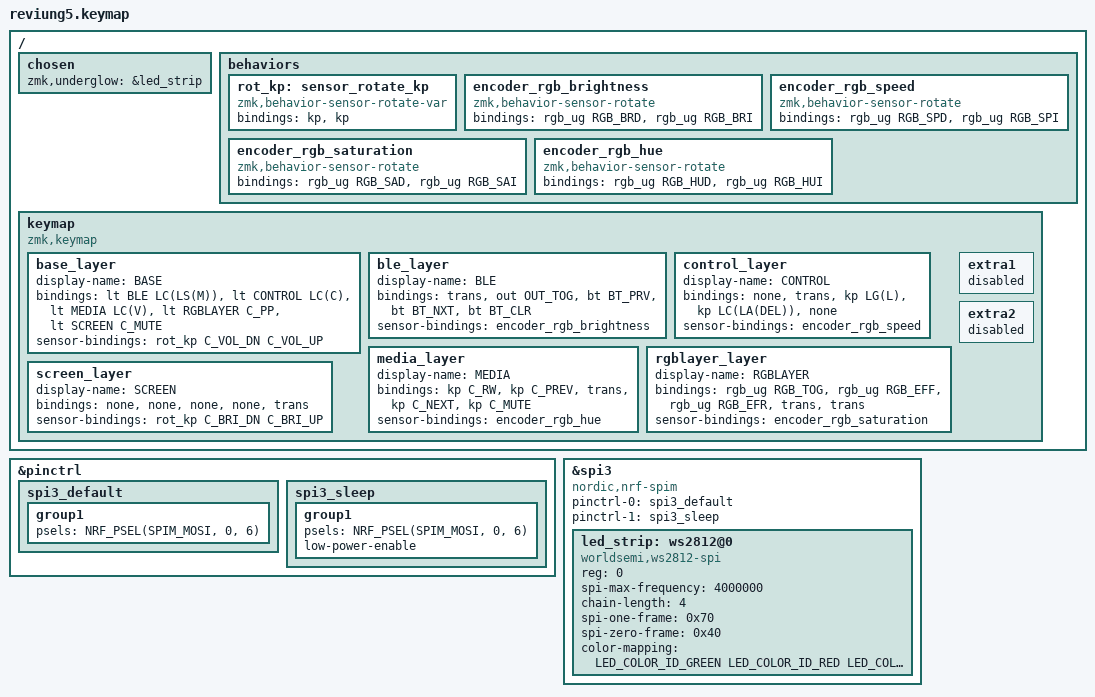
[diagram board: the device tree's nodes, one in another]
/*
 * Copyright (c) 2022 The ZMK Contributors
 *
 * SPDX-License-Identifier: MIT
 */

#include <behaviors.dtsi>
#include <dt-bindings/zmk/keys.h>
#include <dt-bindings/zmk/bt.h>
#include <dt-bindings/zmk/outputs.h>
#include <dt-bindings/led/led.h>
#include <dt-bindings/zmk/rgb.h>

#define BASE 0
#define BLE 1
#define CONTROL 2
#define MEDIA 3
#define RGBLAYER 4
#define SCREEN 5

&pinctrl {
    spi3_default: spi3_default {
        group1 {
            psels = <NRF_PSEL(SPIM_MOSI, 0, 6)>;
        };
    };

    spi3_sleep: spi3_sleep {
        group1 {
            psels = <NRF_PSEL(SPIM_MOSI, 0, 6)>;
            low-power-enable;
        };
    };
};

&spi3 {
    compatible = "nordic,nrf-spim";
    status = "okay";

    pinctrl-0 = <&spi3_default>;
    pinctrl-1 = <&spi3_sleep>;
    pinctrl-names = "default", "sleep";

    led_strip: ws2812@0 {
        compatible = "worldsemi,ws2812-spi";

        /* SPI */
        reg = <0>; /* ignored, but necessary for SPI bindings */
        spi-max-frequency = <4000000>;

        /* WS2812 */
        chain-length = <4>;
        spi-one-frame = <0x70>;
        spi-zero-frame = <0x40>;

        color-mapping = <LED_COLOR_ID_GREEN LED_COLOR_ID_RED LED_COLOR_ID_BLUE>;
    };
};

/ {
    chosen {
        zmk,underglow = &led_strip;
    };
};

/ {
        behaviors {
              rot_kp: sensor_rotate_kp {
                  compatible = "zmk,behavior-sensor-rotate-var";
                  #sensor-binding-cells = <2>;
                  bindings = <&kp>, <&kp>;
              };
              encoder_rgb_brightness: encoder_rgb_brightness {
                  compatible = "zmk,behavior-sensor-rotate";
                  #sensor-binding-cells = <0>;
                  bindings = <&rgb_ug RGB_BRD>, <&rgb_ug RGB_BRI>;
              };
              encoder_rgb_speed: encoder_rgb_speed {
                  compatible = "zmk,behavior-sensor-rotate";
                  #sensor-binding-cells = <0>;
                  bindings = <&rgb_ug RGB_SPD>, <&rgb_ug RGB_SPI>;
              };
              encoder_rgb_saturation: encoder_rgb_saturation {
                  compatible = "zmk,behavior-sensor-rotate";
                  #sensor-binding-cells = <0>;
                  bindings = <&rgb_ug RGB_SAD>, <&rgb_ug RGB_SAI>;
              };
              encoder_rgb_hue: encoder_rgb_hue {
                  compatible = "zmk,behavior-sensor-rotate";
                  #sensor-binding-cells = <0>;
                  bindings = <&rgb_ug RGB_HUD>, <&rgb_ug RGB_HUI>;
              };
          };

        keymap {
            compatible = "zmk,keymap";

            base_layer {
              display-name = "BASE";
              bindings = <
                // ╭───────────────────────┬─────────────────────┬────────────────────┬─────────────────────┬─────────────╮
                     &lt BLE LC(LS(M))   &lt CONTROL LC(C)   &lt MEDIA LC(V)   &lt RGBLAYER C_PP   &lt SCREEN C_MUTE
                // ╰───────────────────────┴─────────────────────┴────────────────────┴─────────────────────┴─────────────╯
              >;
              sensor-bindings = <&rot_kp C_VOL_DN C_VOL_UP>;
            };

            ble_layer {
              display-name = "BLE";
              bindings = <
                // ╭─────────────┬─────────────┬─────────────┬─────────────┬─────────────╮
                     &trans     &out OUT_TOG   &bt BT_PRV    &bt BT_NXT    &bt BT_CLR
                // ╰─────────────┴─────────────┴─────────────┴─────────────┴─────────────╯
              >;
              sensor-bindings = <&encoder_rgb_brightness>;
            };

            control_layer {
              display-name = "CONTROL";
              bindings = <
                // ╭─────────────┬─────────────┬─────────────┬─────────────┬─────────────╮
                     &none     &trans   &kp LG(L)    &kp LC(LA(DEL))    &none
                // ╰─────────────┴─────────────┴─────────────┴─────────────┴─────────────╯
              >;
              sensor-bindings = <&encoder_rgb_speed>;
            };

            media_layer {
              display-name = "MEDIA";
              bindings = <
                // ╭─────────────┬─────────────┬─────────────┬─────────────┬─────────────╮
                      &kp C_RW     &kp C_PREV       &trans     &kp C_NEXT      &kp C_MUTE
                // ╰─────────────┴─────────────┴─────────────┴─────────────┴─────────────╯
              >;
              sensor-bindings = <&encoder_rgb_hue>;
            };

            rgblayer_layer {
              display-name = "RGBLAYER";
              bindings = <
                // ╭─────────────┬─────────────┬─────────────┬─────────────┬─────────────╮
                     &rgb_ug RGB_TOG     &rgb_ug RGB_EFF   &rgb_ug RGB_EFR    &trans    &trans
                // ╰─────────────┴─────────────┴─────────────┴─────────────┴─────────────╯
              >;
              sensor-bindings = <&encoder_rgb_saturation>;
            };

            screen_layer {
              display-name = "SCREEN";
              bindings = <
                // ╭─────────────┬─────────────┬─────────────┬─────────────┬─────────────╮
                     &none     &none   &none    &none    &trans
                // ╰─────────────┴─────────────┴─────────────┴─────────────┴─────────────╯
              >;
              sensor-bindings = <&rot_kp C_BRI_DN	C_BRI_UP>;
            };

            extra1 {
              status = "reserved";
            };

            extra2 {
                status = "reserved";
            };
        };
};
